# LargeDummyDevice register map
File version: 1.0
Registers are 32-bit, read-write, no defined reset value unless marked. A register's access mark holds for its fields unless they carry their own. Offsets are from the block's base; [hi:lo] are bit positions.

## PERIPHERAL_33
Base 0x40020000
0x04 REG_1 — Register 1
  [30:28] FIELD_17, [28] FIELD_22, [28] FIELD_26, [28:27] FIELD_15, [29:27] FIELD_30, [29:26] FIELD_4, [27:26] FIELD_13, [26:25] FIELD_1, [24:21] FIELD_12, [25:21] FIELD_16, [22:21] FIELD_21, [20] FIELD_6, [18] FIELD_3, [21:17] FIELD_7, [18:17] FIELD_11, [21:17] FIELD_24, [21:17] FIELD_27, [16] FIELD_5, [19:16] FIELD_23, [12] FIELD_2, [16:12] FIELD_14, [12] FIELD_28, [13:10] FIELD_18, [9:6] FIELD_9, [9:5] FIELD_10, [5] FIELD_20, [6:3] FIELD_8, [5:3] FIELD_19, [4:0] FIELD_25, [3:0] FIELD_29
0x08 REG_2 — Register 2
  [35:31] FIELD_21, [32:30] FIELD_6, [30] FIELD_14, [32:29] FIELD_16, [33:29] FIELD_20, [29:28] FIELD_8, [28] FIELD_9, [30:28] FIELD_11, [24:23] FIELD_10, [25:23] FIELD_15, [21:19] FIELD_29, [19:18] FIELD_26, [20:16] FIELD_22, [13] FIELD_1, [16:13] FIELD_17, [11:10] FIELD_4, [7] FIELD_7, [8:7] FIELD_13, [8:7] FIELD_23, [9:6] FIELD_3, [5:4] FIELD_27, [6:3] FIELD_2, [6:2] FIELD_18, [6:2] FIELD_28, [4:1] FIELD_5, [2:1] FIELD_19, [1] FIELD_24, [0] FIELD_12, [2:0] FIELD_25
0x0C REG_3 — Register 3
  [33:30] FIELD_11, [31:30] FIELD_24, [33:29] FIELD_13, [29:27] FIELD_21, [26] FIELD_12, [25:24] FIELD_2, [25:23] FIELD_5, [25:22] FIELD_4, [22:19] FIELD_6, [21:19] FIELD_9, [19] FIELD_18, [22:18] FIELD_14, [20:17] FIELD_19, [20:17] FIELD_22, [17] FIELD_23, [16] FIELD_20, [16:15] FIELD_3, [14] FIELD_15, [15:11] FIELD_7, [9] FIELD_17, [10:6] FIELD_10, [5:3] FIELD_8, [5:2] FIELD_16, [4:0] FIELD_1
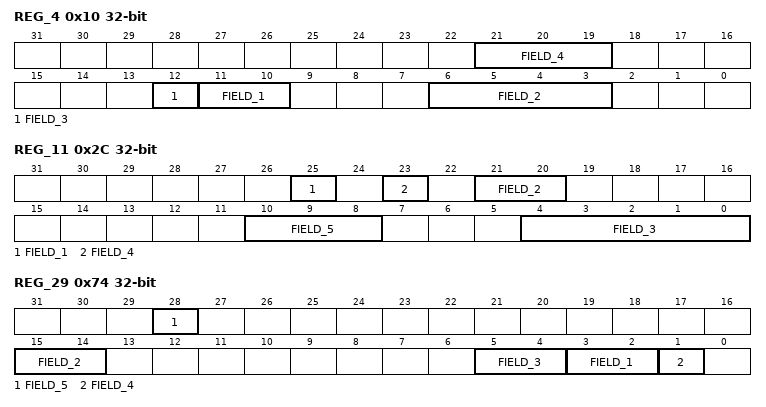
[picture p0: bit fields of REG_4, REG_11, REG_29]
0x10 REG_4 — Register 4
  [21:19] FIELD_4, [12] FIELD_3, [11:10] FIELD_1, [6:3] FIELD_2
0x14 REG_5 — Register 5
  [31:30] FIELD_1, [32:29] FIELD_3, [27] FIELD_4, [21:19] FIELD_7, [17:15] FIELD_2, [18:14] FIELD_6, [14:12] FIELD_5
0x18 REG_6 — Register 6
  [32:30] FIELD_6, [32:29] FIELD_4, [29:28] FIELD_10, [29:27] FIELD_11, [25:23] FIELD_12, [21:19] FIELD_1, [18] FIELD_8, [20:16] FIELD_9, [16:14] FIELD_5, [17:14] FIELD_13, [4] FIELD_3, [7:4] FIELD_7, [5:2] FIELD_2
0x1C REG_7 — Register 7
  [31:30] FIELD_14, [33:30] FIELD_20, [29] FIELD_2, [33:29] FIELD_18, [32:29] FIELD_21, [29:28] FIELD_10, [29:26] FIELD_11, [27:26] FIELD_16, [23:20] FIELD_19, [22:19] FIELD_15, [19] FIELD_23, [19:18] FIELD_1, [21:17] FIELD_9, [15:14] FIELD_3, [16:14] FIELD_4, [15:12] FIELD_7, [15:12] FIELD_12, [12:11] FIELD_5, [10] FIELD_17, [9:7] FIELD_24, [9:5] FIELD_26, [6:4] FIELD_25, [7:4] FIELD_28, [7:3] FIELD_6, [6:3] FIELD_8, [1] FIELD_13, [3:1] FIELD_22, [4:1] FIELD_27
0x20 REG_8 — Register 8
  [31] FIELD_4, [30:28] FIELD_3, [28:25] FIELD_7, [17:14] FIELD_6, [14:13] FIELD_2, [8] FIELD_5, [4:2] FIELD_1
0x24 REG_9 — Register 9
  [32:29] FIELD_5, [33:29] FIELD_13, [29:27] FIELD_10, [27:26] FIELD_3, [22] FIELD_7, [26:22] FIELD_8, [23:20] FIELD_1, [22:20] FIELD_6, [22:19] FIELD_12, [20:18] FIELD_2, [15:14] FIELD_9, [15:14] FIELD_15, [13:10] FIELD_11, [9:7] FIELD_14, [7:6] FIELD_16, [6:4] FIELD_4
0x28 REG_10 — Register 10
  [32:31] FIELD_4, [31:28] FIELD_11, [24:20] FIELD_6, [11:8] FIELD_3, [6:5] FIELD_1, [5] FIELD_5, [6:5] FIELD_7, [9:5] FIELD_9, [2] FIELD_8, [5:2] FIELD_10, [0] FIELD_2
0x2C REG_11 — Register 11
  [25] FIELD_1, [23] FIELD_4, [21:20] FIELD_2, [10:8] FIELD_5, [4:0] FIELD_3
0x30 REG_12 — Register 12
  [23:19] FIELD_4, [19:16] FIELD_2, [16:14] FIELD_1, [15:12] FIELD_5, [13:11] FIELD_3
0x34 REG_13 — Register 13
  [33:31] FIELD_10, [23:21] FIELD_8, [21:20] FIELD_9, [20:17] FIELD_7, [14:13] FIELD_11, [12] FIELD_4, [10:9] FIELD_5, [11:9] FIELD_15, [8:6] FIELD_14, [5:3] FIELD_12, [6:2] FIELD_3, [2] FIELD_13, [5:1] FIELD_2, [3:1] FIELD_6, [0] FIELD_1
0x38 REG_14 — Register 14
  [19] FIELD_2, [22:19] FIELD_6, [18:17] FIELD_1, [17:14] FIELD_5, [14:12] FIELD_9, [10:9] FIELD_8, [5] FIELD_3, [1:0] FIELD_4, [3:0] FIELD_7
0x3C REG_15 — Register 15
  [31] FIELD_12, [33:30] FIELD_4, [28:27] FIELD_9, [25:23] FIELD_5, [19:16] FIELD_3, [14] FIELD_11, [15:13] FIELD_7, [14:12] FIELD_17, [14:10] FIELD_1, [8] FIELD_13, [11:8] FIELD_16, [10:7] FIELD_18, [8:7] FIELD_19, [5] FIELD_6, [5] FIELD_10, [4] FIELD_2, [4] FIELD_8, [3] FIELD_15, [2:1] FIELD_14
0x40 REG_16 — Register 16
  [29] FIELD_1, [29:28] FIELD_14, [29:28] FIELD_30, [31:27] FIELD_26, [29:26] FIELD_20, [26:25] FIELD_16, [29:25] FIELD_24, [27:24] FIELD_17, [28:24] FIELD_19, [23:22] FIELD_12, [22:20] FIELD_8, [20] FIELD_18, [19] FIELD_7, [21:19] FIELD_10, [23:19] FIELD_25, [19:18] FIELD_9, [20:17] FIELD_13, [18:16] FIELD_22, [16:15] FIELD_28, [14] FIELD_21, [12:10] FIELD_5, [13:9] FIELD_4, [13:9] FIELD_15, [9] FIELD_23, [10:9] FIELD_29, [11:7] FIELD_2, [9:7] FIELD_27, [7:6] FIELD_6, [6] FIELD_31, [6:3] FIELD_3, [3] FIELD_11
0x44 REG_17 — Register 17
  [31:28] FIELD_22, [29:27] FIELD_16, [27:25] FIELD_13, [27:24] FIELD_12, [26:23] FIELD_7, [22] FIELD_2, [25:22] FIELD_5, [23:22] FIELD_19, [18:16] FIELD_4, [20:16] FIELD_26, [15:14] FIELD_23, [13] FIELD_14, [13] FIELD_25, [13] FIELD_27, [12:11] FIELD_1, [13:10] FIELD_11, [9] FIELD_15, [8] FIELD_9, [12:8] FIELD_17, [9:8] FIELD_20, [10:6] FIELD_6, [9:6] FIELD_8, [8:6] FIELD_10, [7:4] FIELD_24, [5:2] FIELD_3, [5:1] FIELD_21, [0] FIELD_18
0x48 REG_18 — Register 18
  [34:31] FIELD_3, [30:28] FIELD_4, [28] FIELD_8, [25:24] FIELD_7, [27:24] FIELD_9, [19] FIELD_11, [17] FIELD_5, [16:14] FIELD_10, [8:7] FIELD_1, [4:3] FIELD_2, [2] FIELD_6
0x4C REG_19 — Register 19
  [33:30] FIELD_24, [32:28] FIELD_6, [27] FIELD_9, [29:25] FIELD_11, [28:24] FIELD_13, [26:23] FIELD_7, [23] FIELD_8, [22:19] FIELD_25, [21:18] FIELD_5, [20:18] FIELD_20, [17:16] FIELD_1, [20:16] FIELD_15, [20:16] FIELD_19, [19:15] FIELD_14, [16:14] FIELD_16, [17:13] FIELD_4, [15:13] FIELD_22, [14:12] FIELD_21, [9] FIELD_2, [12:9] FIELD_10, [10:8] FIELD_17, [4] FIELD_12, [6:2] FIELD_3, [2] FIELD_18, [2] FIELD_23
0x50 REG_20 — Register 20
  [33:30] FIELD_17, [29] FIELD_6, [31:29] FIELD_19, [32:28] FIELD_15, [29:26] FIELD_1, [23] FIELD_3, [25:23] FIELD_11, [27:23] FIELD_21, [26:22] FIELD_8, [22:21] FIELD_10, [19] FIELD_16, [17:16] FIELD_14, [17:15] FIELD_2, [16:15] FIELD_7, [16:15] FIELD_13, [16:15] FIELD_20, [12:10] FIELD_9, [10:9] FIELD_5, [13:9] FIELD_23, [10:8] FIELD_18, [7:6] FIELD_22, [5:2] FIELD_4, [4:0] FIELD_12
0x54 REG_21 — Register 21
  [22:21] FIELD_6, [13:12] FIELD_4, [11:10] FIELD_3, [10] FIELD_7, [7:6] FIELD_5, [9:5] FIELD_2, [4:3] FIELD_1
0x58 REG_22 — Register 22
  [33:30] FIELD_1, [33:30] FIELD_5, [31:28] FIELD_3, [28:25] FIELD_4, [7:3] FIELD_6, [2:0] FIELD_2
0x5C REG_23 — Register 23
  [34:31] FIELD_30, [30:28] FIELD_17, [31:28] FIELD_20, [32:28] FIELD_21, [29:27] FIELD_6, [29:27] FIELD_12, [31:27] FIELD_28, [29:25] FIELD_3, [29:25] FIELD_13, [25:22] FIELD_16, [25:21] FIELD_9, [24:21] FIELD_27, [19] FIELD_24, [18:17] FIELD_2, [18:17] FIELD_8, [16] FIELD_18, [19:15] FIELD_1, [16:15] FIELD_22, [15:14] FIELD_10, [13] FIELD_29, [12] FIELD_14, [14:10] FIELD_4, [7] FIELD_26, [4] FIELD_15, [7:3] FIELD_11, [3] FIELD_19, [4:1] FIELD_5, [4:1] FIELD_25, [4:0] FIELD_7, [0] FIELD_23
0x60 REG_24 — Register 24
  [30:29] FIELD_2, [29:28] FIELD_3, [22:21] FIELD_1, [25:21] FIELD_8, [18] FIELD_5, [17:13] FIELD_6, [13] FIELD_11, [15:12] FIELD_4, [8:6] FIELD_7, [6] FIELD_10, [1] FIELD_9
0x64 REG_25 — Register 25
  [31] FIELD_8, [33:29] FIELD_1, [28] FIELD_4, [28:26] FIELD_15, [26:23] FIELD_5, [25:21] FIELD_11, [22:20] FIELD_3, [21:18] FIELD_10, [20:16] FIELD_9, [20:16] FIELD_16, [17:15] FIELD_6, [15:13] FIELD_7, [12] FIELD_13, [11:9] FIELD_2, [10:6] FIELD_12, [4:1] FIELD_14
0x68 REG_26 — Register 26
  [34:31] FIELD_11, [26:25] FIELD_5, [26:24] FIELD_6, [24:22] FIELD_9, [20:19] FIELD_1, [18:16] FIELD_15, [17:15] FIELD_3, [19:15] FIELD_12, [18:14] FIELD_10, [14:11] FIELD_14, [10:6] FIELD_2, [9:6] FIELD_4, [4] FIELD_7, [7:4] FIELD_13, [6:2] FIELD_8
0x6C REG_27 — Register 27
  [31] FIELD_7, [33:30] FIELD_18, [32:30] FIELD_19, [30] FIELD_21, [28:26] FIELD_10, [28:25] FIELD_1, [24] FIELD_8, [26:23] FIELD_6, [24:22] FIELD_24, [22:20] FIELD_20, [20:18] FIELD_15, [18:17] FIELD_9, [20:17] FIELD_12, [20:16] FIELD_11, [17:16] FIELD_16, [18:16] FIELD_23, [13] FIELD_13, [12:11] FIELD_5, [12:11] FIELD_17, [13:9] FIELD_26, [6] FIELD_22, [8:6] FIELD_25, [6:3] FIELD_2, [5:3] FIELD_14, [3:1] FIELD_3, [2:0] FIELD_4
0x70 REG_28 — Register 28
  [33:30] FIELD_2, [31:30] FIELD_7, [33:30] FIELD_20, [32:28] FIELD_24, [31:27] FIELD_1, [30:26] FIELD_4, [24] FIELD_12, [27:23] FIELD_5, [26:22] FIELD_15, [23:21] FIELD_3, [24:21] FIELD_18, [21:20] FIELD_14, [17:16] FIELD_21, [15] FIELD_25, [17:13] FIELD_19, [15:13] FIELD_23, [12] FIELD_17, [12:11] FIELD_8, [13:11] FIELD_10, [11:8] FIELD_22, [7:4] FIELD_6, [7:4] FIELD_9, [4:3] FIELD_13, [4:3] FIELD_16, [5:2] FIELD_11
0x74 REG_29 — Register 29
  [28] FIELD_5, [15:14] FIELD_2, [5:4] FIELD_3, [3:2] FIELD_1, [1] FIELD_4
0x78 REG_30 — Register 30
  [31:28] FIELD_8, [29:25] FIELD_4, [28:25] FIELD_11, [24:23] FIELD_15, [24:22] FIELD_6, [25:22] FIELD_10, [25:22] FIELD_21, [22:20] FIELD_13, [18] FIELD_20, [18:15] FIELD_14, [17:15] FIELD_16, [17:13] FIELD_24, [12] FIELD_7, [14:12] FIELD_28, [13:10] FIELD_17, [11:9] FIELD_3, [13:9] FIELD_22, [11:8] FIELD_19, [12:8] FIELD_26, [10:8] FIELD_27, [11:7] FIELD_18, [11:7] FIELD_23, [7:5] FIELD_5, [8:5] FIELD_9, [6:5] FIELD_30, [6:4] FIELD_2, [5:3] FIELD_25, [4:2] FIELD_1, [2:1] FIELD_29, [4:0] FIELD_12
0x7C REG_31 — Register 31
  [26] FIELD_5, [26] FIELD_6, [27:23] FIELD_7, [22:19] FIELD_2, [17:14] FIELD_3, [11:7] FIELD_1, [3] FIELD_4
0x80 REG_32 — Register 32
  [35:31] FIELD_2, [35:31] FIELD_5, [26] FIELD_4, [19:16] FIELD_1, [16:14] FIELD_3
0x84 REG_33 — Register 33
  [19] FIELD_4, [14:11] FIELD_1, [6] FIELD_3, [6:2] FIELD_5, [4:1] FIELD_2
0x88 REG_34 — Register 34
  [32:31] FIELD_14, [30] FIELD_12, [26:25] FIELD_10, [24:23] FIELD_6, [20] FIELD_5, [19:16] FIELD_4, [16] FIELD_11, [18:15] FIELD_9, [15:14] FIELD_1, [13:12] FIELD_13, [13:11] FIELD_2, [12:9] FIELD_7, [12:8] FIELD_3, [8:5] FIELD_8, [0] FIELD_15
0x8C REG_35 — Register 35
  [15:13] FIELD_2, [13:10] FIELD_1
0x90 REG_36 — Register 36
  [35:31] FIELD_6, [31:30] FIELD_7, [28:26] FIELD_4, [25:23] FIELD_1, [22] FIELD_5, [24:22] FIELD_8, [22:21] FIELD_16, [24:21] FIELD_17, [20] FIELD_10, [20:19] FIELD_12, [19] FIELD_13, [12:9] FIELD_9, [13:9] FIELD_11, [8:6] FIELD_14, [7:6] FIELD_15, [8:5] FIELD_2, [4:2] FIELD_3
0x94 REG_37 — Register 37
  [27:23] FIELD_1, [25:22] FIELD_2
0x98 REG_38 — Register 38
  [33:31] FIELD_9, [30:29] FIELD_16, [30:28] FIELD_6, [28:27] FIELD_22, [31:27] FIELD_25, [29:26] FIELD_15, [29:25] FIELD_8, [26:24] FIELD_13, [24:23] FIELD_1, [23] FIELD_10, [27:23] FIELD_19, [24:21] FIELD_3, [20] FIELD_17, [20:18] FIELD_23, [14] FIELD_4, [17:14] FIELD_12, [17:14] FIELD_21, [16:12] FIELD_2, [10] FIELD_20, [13:9] FIELD_11, [9:6] FIELD_24, [7:4] FIELD_14, [7:3] FIELD_5, [7:3] FIELD_7, [3:2] FIELD_18
0x9C REG_39 — Register 39
  [33:30] FIELD_11, [30:28] FIELD_3, [31:28] FIELD_5, [29:27] FIELD_4, [26:23] FIELD_13, [22:21] FIELD_7, [21] FIELD_10, [20:18] FIELD_14, [16:13] FIELD_12, [9:7] FIELD_1, [8:7] FIELD_15, [6] FIELD_6, [6] FIELD_9, [7:4] FIELD_2, [3:2] FIELD_8
0xA0 REG_40 — Register 40
  [30:26] FIELD_3, [28:25] FIELD_9, [24:20] FIELD_5, [21:20] FIELD_8, [19:17] FIELD_2, [16:14] FIELD_1, [15:12] FIELD_7, [13:10] FIELD_11, [9:7] FIELD_10, [8:6] FIELD_6, [6:5] FIELD_4
0xA4 REG_41 — Register 41
  [32:31] FIELD_1, [32:31] FIELD_3, [31:30] FIELD_4, [33:29] FIELD_6, [27:23] FIELD_8, [26:22] FIELD_12, [26:22] FIELD_14, [20:16] FIELD_2, [14] FIELD_7, [13:10] FIELD_5, [8] FIELD_10, [7:6] FIELD_11, [8:4] FIELD_9, [5:3] FIELD_13, [3] FIELD_15
0xA8 REG_42 — Register 42
  [30] FIELD_20, [31:30] FIELD_30, [32:29] FIELD_9, [28] FIELD_27, [28:27] FIELD_19, [30:27] FIELD_23, [25:24] FIELD_1, [24:22] FIELD_8, [22:19] FIELD_12, [20:19] FIELD_28, [20:19] FIELD_32, [22:18] FIELD_10, [18] FIELD_18, [17] FIELD_13, [18:16] FIELD_14, [19:16] FIELD_29, [16:15] FIELD_3, [17:15] FIELD_11, [19:15] FIELD_17, [16:13] FIELD_5, [17:13] FIELD_21, [13:12] FIELD_24, [12:11] FIELD_25, [10] FIELD_6, [12:9] FIELD_7, [13:9] FIELD_16, [11:8] FIELD_26, [9:5] FIELD_2, [4] FIELD_4, [7:4] FIELD_22, [7:4] FIELD_31, [2] FIELD_15
0xAC REG_43 — Register 43
  [35:31] FIELD_12, [34:31] FIELD_25, [28:26] FIELD_2, [30:26] FIELD_8, [27:26] FIELD_14, [28:26] FIELD_17, [28:25] FIELD_9, [27:24] FIELD_5, [27:24] FIELD_11, [24] FIELD_13, [26:22] FIELD_15, [22] FIELD_22, [23:21] FIELD_6, [23:21] FIELD_27, [21] FIELD_30, [21:20] FIELD_20, [17:16] FIELD_1, [16:15] FIELD_4, [18:14] FIELD_28, [16:13] FIELD_7, [13] FIELD_26, [12:11] FIELD_19, [14:10] FIELD_29, [9] FIELD_24, [7] FIELD_3, [11:7] FIELD_16, [7] FIELD_21, [5:4] FIELD_18, [7:4] FIELD_23, [4:2] FIELD_10
0xB0 REG_44 — Register 44
  [34:31] FIELD_7, [34:30] FIELD_4, [30] FIELD_20, [33:30] FIELD_26, [30:28] FIELD_22, [28:26] FIELD_13, [28:25] FIELD_17, [29:25] FIELD_25, [27:25] FIELD_28, [27:24] FIELD_21, [27:23] FIELD_8, [26:23] FIELD_16, [27:23] FIELD_18, [25:22] FIELD_14, [22] FIELD_19, [24:21] FIELD_10, [22:20] FIELD_5, [21:19] FIELD_6, [16:15] FIELD_11, [18:15] FIELD_29, [14] FIELD_24, [17:13] FIELD_12, [16:13] FIELD_15, [12:9] FIELD_1, [10:8] FIELD_23, [7:6] FIELD_3, [6:2] FIELD_2, [2] FIELD_9, [5:2] FIELD_27
0xB4 REG_45 — Register 45
  [32:31] FIELD_4, [33:29] FIELD_12, [27:25] FIELD_5, [25:24] FIELD_13, [22] FIELD_6, [21] FIELD_7, [25:21] FIELD_23, [21:19] FIELD_2, [19:18] FIELD_10, [18] FIELD_21, [18] FIELD_22, [17] FIELD_9, [12:11] FIELD_16, [11:10] FIELD_24, [12:9] FIELD_1, [13:9] FIELD_3, [11:9] FIELD_15, [8:7] FIELD_11, [11:7] FIELD_18, [8:6] FIELD_14, [7:3] FIELD_20, [5:1] FIELD_17, [1:0] FIELD_8, [1:0] FIELD_19
0xB8 REG_46 — Register 46
  [32:30] FIELD_2, [32:28] FIELD_1, [14] FIELD_3, [12:10] FIELD_4, [5] FIELD_5
0xBC REG_47 — Register 47
  [34:30] FIELD_1, [28] FIELD_12, [27:26] FIELD_2, [30:26] FIELD_7, [27:23] FIELD_5, [23] FIELD_10, [24:21] FIELD_4, [17] FIELD_13, [14:13] FIELD_11, [9] FIELD_8, [2] FIELD_6, [1] FIELD_9, [1:0] FIELD_3
0xC0 REG_48 — Register 48
  [26:23] FIELD_1
0xC4 REG_49 — Register 49
  [33:30] FIELD_12, [29] FIELD_13, [26:24] FIELD_20, [24:22] FIELD_10, [23:21] FIELD_5, [20] FIELD_3, [24:20] FIELD_17, [24:20] FIELD_18, [17:16] FIELD_1, [17:15] FIELD_6, [17:15] FIELD_19, [17:14] FIELD_8, [18:14] FIELD_9, [14:13] FIELD_14, [17:13] FIELD_22, [14:12] FIELD_16, [12:10] FIELD_4, [11:10] FIELD_23, [9:8] FIELD_2, [9:7] FIELD_21, [8:7] FIELD_26, [11:7] FIELD_28, [10:6] FIELD_27, [4] FIELD_11, [5:4] FIELD_15, [7:3] FIELD_24, [5:2] FIELD_25, [1:0] FIELD_7
0xC8 REG_50 — Register 50
  [12:9] FIELD_1
